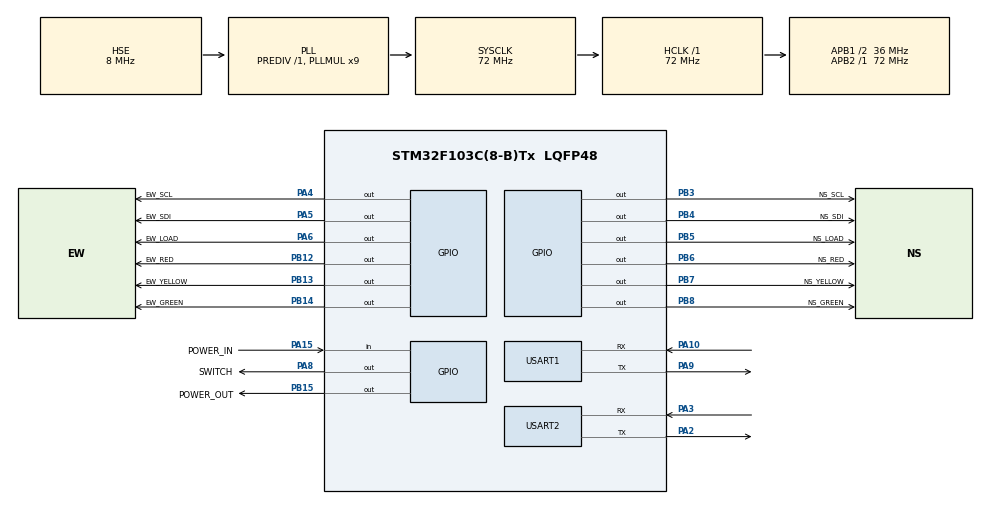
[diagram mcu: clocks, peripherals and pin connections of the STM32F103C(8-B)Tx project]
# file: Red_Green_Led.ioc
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Mcu.Family=STM32F1
Mcu.Name=STM32F103C(8-B)Tx
Mcu.Package=LQFP48
NVIC.PriorityGroup=NVIC_PRIORITYGROUP_4
NVIC.TIM2_IRQn=true\:0\:0\:false\:false\:true\:true\:true\:true
NVIC.USART1_IRQn=true\:0\:0\:false\:false\:true\:true\:true\:true
NVIC.USART2_IRQn=true\:0\:0\:false\:false\:true\:true\:true\:true
PA10.Mode=Asynchronous
PA10.Signal=USART1_RX
PA13.Mode=Serial_Wire
PA13.Signal=SYS_JTMS-SWDIO
PA14.Mode=Serial_Wire
PA14.Signal=SYS_JTCK-SWCLK
PA15.GPIO_Label=POWER_IN
PA15.GPIO_PuPd=GPIO_PULLUP
PA15.Signal=GPIO_Input
PA2.Mode=Asynchronous
PA2.Signal=USART2_TX
PA3.Mode=Asynchronous
PA3.Signal=USART2_RX
PA4.GPIO_Label=EW_SCL
PA4.GPIO_Speed=GPIO_SPEED_FREQ_LOW
PA4.Signal=GPIO_Output
PA5.GPIO_Label=EW_SDI
PA5.GPIO_Speed=GPIO_SPEED_FREQ_LOW
PA5.Signal=GPIO_Output
PA6.GPIO_Label=EW_LOAD
PA6.GPIO_Speed=GPIO_SPEED_FREQ_LOW
PA6.Signal=GPIO_Output
PA8.GPIO_Label=SWITCH
PA8.GPIO_Speed=GPIO_SPEED_FREQ_HIGH
PA8.Signal=GPIO_Output
PA9.Mode=Asynchronous
PA9.Signal=USART1_TX
PB12.GPIO_Label=EW_RED
PB12.GPIO_Speed=GPIO_SPEED_FREQ_HIGH
PB12.Signal=GPIO_Output
PB13.GPIO_Label=EW_YELLOW
PB13.GPIO_Speed=GPIO_SPEED_FREQ_HIGH
PB13.Signal=GPIO_Output
PB14.GPIO_Label=EW_GREEN
PB14.GPIO_Speed=GPIO_SPEED_FREQ_HIGH
PB14.Signal=GPIO_Output
PB15.GPIO_Label=POWER_OUT
PB15.GPIO_Speed=GPIO_SPEED_FREQ_HIGH
PB15.PinState=GPIO_PIN_RESET
PB15.Signal=GPIO_Output
PB3.GPIO_Label=NS_SCL
PB3.GPIO_Speed=GPIO_SPEED_FREQ_LOW
PB3.Signal=GPIO_Output
PB4.GPIO_Label=NS_SDI
PB4.GPIO_Speed=GPIO_SPEED_FREQ_LOW
PB4.Signal=GPIO_Output
PB5.GPIO_Label=NS_LOAD
PB5.GPIO_Speed=GPIO_SPEED_FREQ_LOW
PB5.Signal=GPIO_Output
PB6.GPIO_Label=NS_RED
PB6.GPIO_Speed=GPIO_SPEED_FREQ_HIGH
PB6.Signal=GPIO_Output
PB7.GPIO_Label=NS_YELLOW
PB7.GPIO_Speed=GPIO_SPEED_FREQ_HIGH
PB7.Signal=GPIO_Output
PB8.GPIO_Label=NS_GREEN
PB8.GPIO_Speed=GPIO_SPEED_FREQ_HIGH
PB8.Signal=GPIO_Output
PD0-OSC_IN.Mode=HSE-External-Oscillator
PD0-OSC_IN.Signal=RCC_OSC_IN
PD1-OSC_OUT.Mode=HSE-External-Oscillator
PD1-OSC_OUT.Signal=RCC_OSC_OUT
ProjectManager.HeapSize=0x200
ProjectManager.StackSize=0x400
ProjectManager.TargetToolchain=MDK-ARM V5.32
RCC.AHBFreq_Value=72000000
RCC.APB1CLKDivider=RCC_HCLK_DIV2
RCC.APB1Freq_Value=36000000
RCC.APB1TimFreq_Value=72000000
RCC.APB2Freq_Value=72000000
RCC.APB2TimFreq_Value=72000000
RCC.HCLKFreq_Value=72000000
RCC.PLLMUL=RCC_PLL_MUL9
RCC.PLLSourceVirtual=RCC_PLLSOURCE_HSE
RCC.SYSCLKFreq_VALUE=72000000
RCC.SYSCLKSource=RCC_SYSCLKSOURCE_PLLCLK
RCC.USBFreq_Value=72000000
TIM2.Period=9
TIM2.Prescaler=7199
USART1.VirtualMode=VM_ASYNC
USART2.VirtualMode=VM_ASYNC
VP_TIM2_VS_ClockSourceINT.Mode=Internal
board=custom

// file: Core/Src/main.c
/* USER CODE BEGIN Header */
/**
  ******************************************************************************
  * @file           : main.c
  * @brief          : Main program body
  ******************************************************************************
  * @attention
  *
  * Copyright (c) 2025 STMicroelectronics.
  * All rights reserved.
  *
  * This software is licensed under terms that can be found in the LICENSE file
  * in the root directory of this software component.
  * If no LICENSE file comes with this software, it is provided AS-IS.
  *
  ******************************************************************************
  */
/* USER CODE END Header */
#include "main.h"
#include "tim.h"
#include "usart.h"
#include "gpio.h"

/* USER CODE BEGIN Includes */
#include "Nixie.h"
#include "Key.h"
#include "stdio.h"
#include "APP.h"
/* USER CODE END Includes */

void SystemClock_Config(void);

int main(void)
{

  /* MCU Configuration--------------------------------------------------------*/

  /* Reset of all peripherals, Initializes the Flash interface and the Systick. */
  HAL_Init();

  /* Configure the system clock */
  SystemClock_Config();

  /* Initialize all configured peripherals */
  MX_GPIO_Init();
  MX_USART1_UART_Init();
  MX_TIM2_Init();
  MX_USART2_UART_Init();
  /* USER CODE BEGIN 2 */
	HAL_GPIO_WritePin(POWER_OUT_GPIO_Port,POWER_OUT_Pin, GPIO_PIN_SET);
	HAL_GPIO_WritePin(SWITCH_GPIO_Port,SWITCH_Pin, GPIO_PIN_SET);
	button_init(&btn1, read_button1_GPIO, 0);
	button_attach(&btn1, DOUBLE_CLICK,BTN1_DOUBLE_Click_Handler);
	button_start(&btn1);
	HAL_TIM_Base_Start_IT(&htim2);
	HAL_UART_Receive_IT(&huart1,&usart_buf,1);
	HAL_Delay(2000);
	HAL_UART_Receive_IT(&huart2,&usart_buf,1);
	Usart_Init();
  /* USER CODE END 2 */

  /* Infinite loop */
  while (1)
  {

  }
}

void SystemClock_Config(void)
{
  RCC_OscInitTypeDef RCC_OscInitStruct = {0};
  RCC_ClkInitTypeDef RCC_ClkInitStruct = {0};

  /** Initializes the RCC Oscillators according to the specified parameters
  * in the RCC_OscInitTypeDef structure.
  */
  RCC_OscInitStruct.OscillatorType = RCC_OSCILLATORTYPE_HSE;
  RCC_OscInitStruct.HSEState = RCC_HSE_ON;
  RCC_OscInitStruct.HSEPredivValue = RCC_HSE_PREDIV_DIV1;
  RCC_OscInitStruct.HSIState = RCC_HSI_ON;
  RCC_OscInitStruct.PLL.PLLState = RCC_PLL_ON;
  RCC_OscInitStruct.PLL.PLLSource = RCC_PLLSOURCE_HSE;
  RCC_OscInitStruct.PLL.PLLMUL = RCC_PLL_MUL9;
  if (HAL_RCC_OscConfig(&RCC_OscInitStruct) != HAL_OK)
  {
    Error_Handler();
  }

  /** Initializes the CPU, AHB and APB buses clocks
  */
  RCC_ClkInitStruct.ClockType = RCC_CLOCKTYPE_HCLK|RCC_CLOCKTYPE_SYSCLK
                              |RCC_CLOCKTYPE_PCLK1|RCC_CLOCKTYPE_PCLK2;
  RCC_ClkInitStruct.SYSCLKSource = RCC_SYSCLKSOURCE_PLLCLK;
  RCC_ClkInitStruct.AHBCLKDivider = RCC_SYSCLK_DIV1;
  RCC_ClkInitStruct.APB1CLKDivider = RCC_HCLK_DIV2;
  RCC_ClkInitStruct.APB2CLKDivider = RCC_HCLK_DIV1;

  if (HAL_RCC_ClockConfig(&RCC_ClkInitStruct, FLASH_LATENCY_2) != HAL_OK)
  {
    Error_Handler();
  }
}

void Error_Handler(void)
{
  __disable_irq();
  while (1)
  {
  }
}
